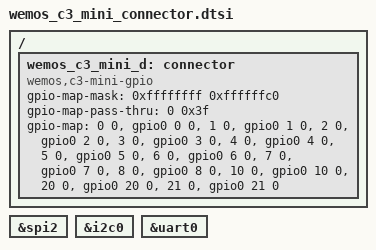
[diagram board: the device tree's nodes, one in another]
/*
 * SPDX-License-Identifier: Apache-2.0
 */

/ {
	wemos_c3_mini_d: connector {
		compatible = "wemos,c3-mini-gpio";
		#gpio-cells = <2>;
		gpio-map-mask = <0xffffffff 0xffffffc0>;
		gpio-map-pass-thru = <0 0x3f>;
		gpio-map = <0 0 &gpio0 0 0>, /* D6 */
		           <1 0 &gpio0 1 0>, /* D5 */
		           <2 0 &gpio0 2 0>, /* D0 */
		           <3 0 &gpio0 3 0>, /* A0 */
		           <4 0 &gpio0 4 0>, /* D7 */
		           <5 0 &gpio0 5 0>, /* D8 */
		           <6 0 &gpio0 6 0>, /* D4 */
		           <7 0 &gpio0 7 0>, /* D3 */
		           <8 0 &gpio0 8 0>, /* D2 */
		           <10 0 &gpio0 10 0>,  /* D1 */
		           <20 0 &gpio0 20 0>,  /* RX */
		           <21 0 &gpio0 21 0>;  /* TX */
	};
};

wemos_c3_mini_spi: &spi2 {};
wemos_c3_mini_i2c: &i2c0 {};
wemos_c3_mini_serial: &uart0 {};
